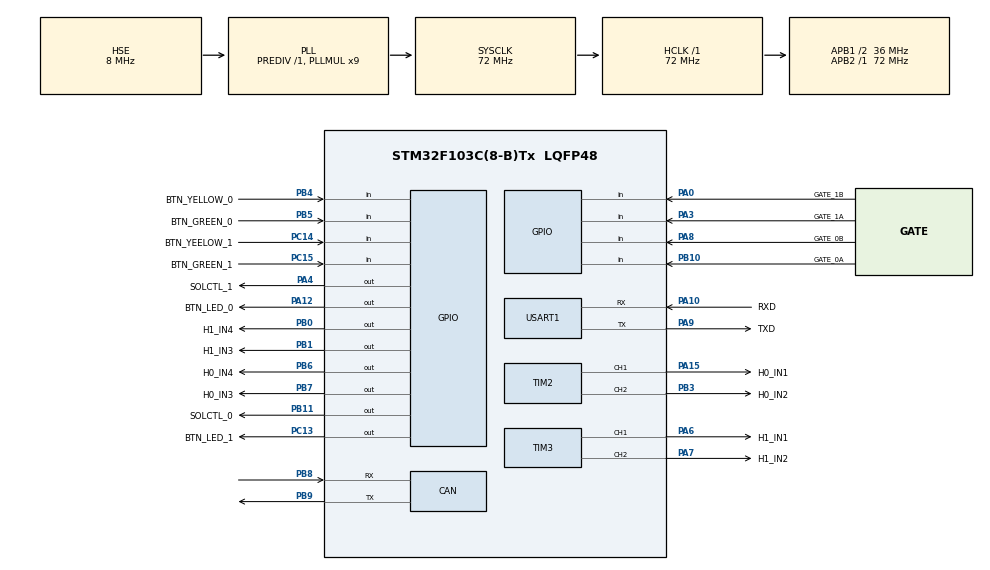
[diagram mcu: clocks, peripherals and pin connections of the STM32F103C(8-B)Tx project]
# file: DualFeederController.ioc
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CAN.CalculateTimeBit=1333
CAN.CalculateTimeQuantum=444.44444444444446
FREERTOS.Tasks01=defaultTask,0,128,StartDefaultTask,Default,NULL
Mcu.Family=STM32F1
Mcu.Name=STM32F103C(8-B)Tx
Mcu.Package=LQFP48
NVIC.PriorityGroup=NVIC_PRIORITYGROUP_4
NVIC.TIM4_IRQn=true\:0\:0\:false\:false\:true\:false\:false\:true
NVIC.TimeBase=TIM4_IRQn
NVIC.TimeBaseIP=TIM4
PA0-WKUP.GPIO_Label=GATE_1B
PA0-WKUP.Signal=GPIO_Input
PA10.GPIO_Label=RXD
PA10.Mode=Asynchronous
PA10.Signal=USART1_RX
PA12.GPIO_Label=BTN_LED_0
PA12.Signal=GPIO_Output
PA13.Mode=Serial_Wire
PA13.Signal=SYS_JTMS-SWDIO
PA14.Mode=Serial_Wire
PA14.Signal=SYS_JTCK-SWCLK
PA15.GPIO_Label=H0_IN1
PA15.Signal=S_TIM2_CH1_ETR
PA3.GPIO_Label=GATE_1A
PA3.Signal=GPIO_Input
PA4.GPIO_Label=SOLCTL_1
PA4.Signal=GPIO_Output
PA6.GPIO_Label=H1_IN1
PA6.Signal=S_TIM3_CH1
PA7.GPIO_Label=H1_IN2
PA7.Signal=S_TIM3_CH2
PA8.GPIO_Label=GATE_0B
PA8.Signal=GPIO_Input
PA9.GPIO_Label=TXD
PA9.Mode=Asynchronous
PA9.Signal=USART1_TX
PB0.GPIO_Label=H1_IN4
PB0.Signal=GPIO_Output
PB1.GPIO_Label=H1_IN3
PB1.Signal=GPIO_Output
PB10.GPIO_Label=GATE_0A
PB10.Signal=GPIO_Input
PB11.GPIO_Label=SOLCTL_0
PB11.Signal=GPIO_Output
PB3.GPIO_Label=H0_IN2
PB3.Signal=S_TIM2_CH2
PB4.GPIO_Label=BTN_YELLOW_0
PB4.Signal=GPIO_Input
PB5.GPIO_Label=BTN_GREEN_0
PB5.Signal=GPIO_Input
PB6.GPIO_Label=H0_IN4
PB6.Signal=GPIO_Output
PB7.GPIO_Label=H0_IN3
PB7.Signal=GPIO_Output
PB8.Mode=Master
PB8.Signal=CAN_RX
PB9.Mode=Master
PB9.Signal=CAN_TX
PC13-TAMPER-RTC.GPIO_Label=BTN_LED_1
PC13-TAMPER-RTC.Signal=GPIO_Output
PC14-OSC32_IN.GPIO_Label=BTN_YEELOW_1
PC14-OSC32_IN.Signal=GPIO_Input
PC15-OSC32_OUT.GPIO_Label=BTN_GREEN_1
PC15-OSC32_OUT.Signal=GPIO_Input
PD0-OSC_IN.Mode=HSE-External-Oscillator
PD0-OSC_IN.Signal=RCC_OSC_IN
PD1-OSC_OUT.Mode=HSE-External-Oscillator
PD1-OSC_OUT.Signal=RCC_OSC_OUT
ProjectManager.HeapSize=0x200
ProjectManager.StackSize=0x400
ProjectManager.TargetToolchain=MDK-ARM V5
RCC.AHBFreq_Value=72000000
RCC.APB1CLKDivider=RCC_HCLK_DIV2
RCC.APB1Freq_Value=36000000
RCC.APB1TimFreq_Value=72000000
RCC.APB2Freq_Value=72000000
RCC.APB2TimFreq_Value=72000000
RCC.HCLKFreq_Value=72000000
RCC.PLLMUL=RCC_PLL_MUL9
RCC.PLLSourceVirtual=RCC_PLLSOURCE_HSE
RCC.SYSCLKFreq_VALUE=72000000
RCC.SYSCLKSource=RCC_SYSCLKSOURCE_PLLCLK
RCC.USBFreq_Value=72000000
SH.S_TIM2_CH1_ETR.0=TIM2_CH1,PWM Generation1 CH1
SH.S_TIM2_CH2.0=TIM2_CH2,PWM Generation2 CH2
SH.S_TIM3_CH1.0=TIM3_CH1,PWM Generation1 CH1
SH.S_TIM3_CH2.0=TIM3_CH2,PWM Generation2 CH2
TIM2.Channel-PWM\ Generation1\ CH1=TIM_CHANNEL_1
TIM2.Channel-PWM\ Generation2\ CH2=TIM_CHANNEL_2
TIM3.Channel-PWM\ Generation1\ CH1=TIM_CHANNEL_1
TIM3.Channel-PWM\ Generation2\ CH2=TIM_CHANNEL_2
USART1.VirtualMode=VM_ASYNC
VP_FREERTOS_VS_CMSIS_V1.Mode=CMSIS_V1
VP_SYS_VS_tim4.Mode=TIM4
board=custom

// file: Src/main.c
/* USER CODE BEGIN Header */
/**
  ******************************************************************************
  * @file           : main.c
  * @brief          : Main program body
  ******************************************************************************
  * @attention
  *
  * <h2><center>&copy; Copyright (c) 2019 STMicroelectronics.
  * All rights reserved.</center></h2>
  *
  * This software component is licensed by ST under Ultimate Liberty license
  * SLA0044, the "License"; You may not use this file except in compliance with
  * the License. You may obtain a copy of the License at:
  *                             www.st.com/SLA0044
  *
  ******************************************************************************
  */
/* USER CODE END Header */

#include "main.h"
#include "cmsis_os.h"

CAN_HandleTypeDef hcan;

TIM_HandleTypeDef htim2;
TIM_HandleTypeDef htim3;

UART_HandleTypeDef huart1;

osThreadId defaultTaskHandle;

void SystemClock_Config(void);
static void MX_GPIO_Init(void);
static void MX_CAN_Init(void);
static void MX_USART1_UART_Init(void);
static void MX_TIM2_Init(void);
static void MX_TIM3_Init(void);
void StartDefaultTask(void const * argument);

/* USER CODE BEGIN 0 */
#if 1
#pragma import(__use_no_semihosting)
//标准库需要的支持函数
struct __FILE
{
	int handle;
};

FILE __stdout;
//定义_sys_exit()以避免使用半主机模式
void _sys_exit(int x)
{
	x = x;
}
//重定义fputc函数
int fputc(int ch, FILE *f)
{
	while((USART1->SR&0X40)==0);//循环发送,直到发送完毕
	USART1->DR = (uint8_t) ch;
	return ch;
}
#endif
/* USER CODE END 0 */

int main(void)
{

  /* MCU Configuration--------------------------------------------------------*/

  /* Reset of all peripherals, Initializes the Flash interface and the Systick. */
  HAL_Init();

  /* Configure the system clock */
  SystemClock_Config();

  /* Initialize all configured peripherals */
  MX_GPIO_Init();
  MX_CAN_Init();
  MX_USART1_UART_Init();
  MX_TIM2_Init();
  MX_TIM3_Init();
  /* USER CODE BEGIN 2 */

  printf("System ON\r\n");

  while(1)
  {
	  // 按键部分测试
//	  printf("BTN_GREEN_1 = %d  ", HAL_GPIO_ReadPin(BTN_GREEN_1_GPIO_Port, BTN_GREEN_1_Pin));  // 待机状态为 0
//	  printf("BTN_YELLOW_1 = %d\r\n", HAL_GPIO_ReadPin(BTN_YELLOW_1_GPIO_Port, BTN_YELLOW_1_Pin));  // 待机状态为 0
//	  HAL_GPIO_TogglePin(BTN_LED_1_GPIO_Port, BTN_LED_1_Pin);
//	  HAL_GPIO_WritePin(BTN_LED_1_GPIO_Port, BTN_LED_1_Pin, GPIO_PIN_SET);        // 待机状态为 0

	  // 后部光电开关测试
//	  printf("LIGH_GATE1B = %d\r\n", HAL_GPIO_ReadPin(GATE_1B_GPIO_Port, GATE_1B_Pin));   // 待机状态为 0

	  // 后部电机测试
//	  HAL_GPIO_WritePin(H1_IN3_GPIO_Port, H1_IN3_Pin , GPIO_PIN_RESET);
//	  HAL_GPIO_WritePin(H1_IN4_GPIO_Port, H1_IN4_Pin , GPIO_PIN_SET);

	  // 光电开关配合和电机测试
//	  if(HAL_GPIO_ReadPin(GATE_1B_GPIO_Port, GATE_1B_Pin) == GPIO_PIN_RESET)
//	  {
//		  HAL_GPIO_WritePin(H1_IN3_GPIO_Port, H1_IN3_Pin , GPIO_PIN_RESET);
//		  HAL_GPIO_WritePin(H1_IN4_GPIO_Port, H1_IN4_Pin , GPIO_PIN_SET);
//	  }
//	  else
//	  {
//		  // 刹车测试
//		  HAL_GPIO_WritePin(H1_IN3_GPIO_Port, H1_IN3_Pin , GPIO_PIN_SET);
//		  HAL_GPIO_WritePin(H1_IN4_GPIO_Port, H1_IN4_Pin , GPIO_PIN_SET);
//	  }

	  // 电磁挡板测试
//	  if(HAL_GPIO_ReadPin(BTN_YELLOW_1_GPIO_Port, BTN_YELLOW_1_Pin) == GPIO_PIN_SET)
//	  {
//		  HAL_GPIO_WritePin(SOLCTL_1_GPIO_Port, SOLCTL_1_Pin , GPIO_PIN_SET);
//	  }
//	  else
//	  {
//		  HAL_GPIO_WritePin(SOLCTL_1_GPIO_Port, SOLCTL_1_Pin , GPIO_PIN_RESET);
//	  }

//	  // 前部电机测试, 正转
//	  TIM3->CCR1 = 0;
//	  TIM3->CCR2 = 1000;
//	  HAL_TIM_PWM_Start(&htim3, TIM_CHANNEL_1);
//	  HAL_TIM_PWM_Start(&htim3, TIM_CHANNEL_2);

//	  // 前部光电开关测试
//	  printf("LIGH_GATE1A = %d\r\n", HAL_GPIO_ReadPin(GATE_1A_GPIO_Port, GATE_1A_Pin));

	  HAL_Delay(20);
  }

  /* USER CODE END 2 */

  /* Create the thread(s) */
  /* definition and creation of defaultTask */
  osThreadDef(defaultTask, StartDefaultTask, osPriorityNormal, 0, 128);
  defaultTaskHandle = osThreadCreate(osThread(defaultTask), NULL);

  /* Start scheduler */
  osKernelStart();

  /* We should never get here as control is now taken by the scheduler */

  /* Infinite loop */
  while (1)
  {

  }
}

void SystemClock_Config(void)
{
  RCC_OscInitTypeDef RCC_OscInitStruct = {0};
  RCC_ClkInitTypeDef RCC_ClkInitStruct = {0};

  /** Initializes the CPU, AHB and APB busses clocks
  */
  RCC_OscInitStruct.OscillatorType = RCC_OSCILLATORTYPE_HSE;
  RCC_OscInitStruct.HSEState = RCC_HSE_ON;
  RCC_OscInitStruct.HSEPredivValue = RCC_HSE_PREDIV_DIV1;
  RCC_OscInitStruct.HSIState = RCC_HSI_ON;
  RCC_OscInitStruct.PLL.PLLState = RCC_PLL_ON;
  RCC_OscInitStruct.PLL.PLLSource = RCC_PLLSOURCE_HSE;
  RCC_OscInitStruct.PLL.PLLMUL = RCC_PLL_MUL9;
  if (HAL_RCC_OscConfig(&RCC_OscInitStruct) != HAL_OK)
  {
    Error_Handler();
  }
  /** Initializes the CPU, AHB and APB busses clocks
  */
  RCC_ClkInitStruct.ClockType = RCC_CLOCKTYPE_HCLK|RCC_CLOCKTYPE_SYSCLK
                              |RCC_CLOCKTYPE_PCLK1|RCC_CLOCKTYPE_PCLK2;
  RCC_ClkInitStruct.SYSCLKSource = RCC_SYSCLKSOURCE_PLLCLK;
  RCC_ClkInitStruct.AHBCLKDivider = RCC_SYSCLK_DIV1;
  RCC_ClkInitStruct.APB1CLKDivider = RCC_HCLK_DIV2;
  RCC_ClkInitStruct.APB2CLKDivider = RCC_HCLK_DIV1;

  if (HAL_RCC_ClockConfig(&RCC_ClkInitStruct, FLASH_LATENCY_2) != HAL_OK)
  {
    Error_Handler();
  }
}

static void MX_CAN_Init(void)
{

  hcan.Instance = CAN1;
  hcan.Init.Prescaler = 16;
  hcan.Init.Mode = CAN_MODE_NORMAL;
  hcan.Init.SyncJumpWidth = CAN_SJW_1TQ;
  hcan.Init.TimeSeg1 = CAN_BS1_1TQ;
  hcan.Init.TimeSeg2 = CAN_BS2_1TQ;
  hcan.Init.TimeTriggeredMode = DISABLE;
  hcan.Init.AutoBusOff = DISABLE;
  hcan.Init.AutoWakeUp = DISABLE;
  hcan.Init.AutoRetransmission = DISABLE;
  hcan.Init.ReceiveFifoLocked = DISABLE;
  hcan.Init.TransmitFifoPriority = DISABLE;
  if (HAL_CAN_Init(&hcan) != HAL_OK)
  {
    Error_Handler();
  }

}

static void MX_TIM2_Init(void)
{

  TIM_MasterConfigTypeDef sMasterConfig = {0};
  TIM_OC_InitTypeDef sConfigOC = {0};

  htim2.Instance = TIM2;
  htim2.Init.Prescaler = 6;
  htim2.Init.CounterMode = TIM_COUNTERMODE_UP;
  htim2.Init.Period = 1000;
  htim2.Init.ClockDivision = TIM_CLOCKDIVISION_DIV1;
  htim2.Init.AutoReloadPreload = TIM_AUTORELOAD_PRELOAD_DISABLE;
  if (HAL_TIM_PWM_Init(&htim2) != HAL_OK)
  {
    Error_Handler();
  }
  sMasterConfig.MasterOutputTrigger = TIM_TRGO_RESET;
  sMasterConfig.MasterSlaveMode = TIM_MASTERSLAVEMODE_DISABLE;
  if (HAL_TIMEx_MasterConfigSynchronization(&htim2, &sMasterConfig) != HAL_OK)
  {
    Error_Handler();
  }
  sConfigOC.OCMode = TIM_OCMODE_PWM1;
  sConfigOC.Pulse = 0;
  sConfigOC.OCPolarity = TIM_OCPOLARITY_HIGH;
  sConfigOC.OCFastMode = TIM_OCFAST_DISABLE;
  if (HAL_TIM_PWM_ConfigChannel(&htim2, &sConfigOC, TIM_CHANNEL_1) != HAL_OK)
  {
    Error_Handler();
  }
  if (HAL_TIM_PWM_ConfigChannel(&htim2, &sConfigOC, TIM_CHANNEL_2) != HAL_OK)
  {
    Error_Handler();
  }
  HAL_TIM_MspPostInit(&htim2);

}

static void MX_TIM3_Init(void)
{

  TIM_MasterConfigTypeDef sMasterConfig = {0};
  TIM_OC_InitTypeDef sConfigOC = {0};

  htim3.Instance = TIM3;
  htim3.Init.Prescaler = 6;
  htim3.Init.CounterMode = TIM_COUNTERMODE_UP;
  htim3.Init.Period = 1000;
  htim3.Init.ClockDivision = TIM_CLOCKDIVISION_DIV1;
  htim3.Init.AutoReloadPreload = TIM_AUTORELOAD_PRELOAD_DISABLE;
  if (HAL_TIM_PWM_Init(&htim3) != HAL_OK)
  {
    Error_Handler();
  }
  sMasterConfig.MasterOutputTrigger = TIM_TRGO_RESET;
  sMasterConfig.MasterSlaveMode = TIM_MASTERSLAVEMODE_DISABLE;
  if (HAL_TIMEx_MasterConfigSynchronization(&htim3, &sMasterConfig) != HAL_OK)
  {
    Error_Handler();
  }
  sConfigOC.OCMode = TIM_OCMODE_PWM1;
  sConfigOC.Pulse = 0;
  sConfigOC.OCPolarity = TIM_OCPOLARITY_HIGH;
  sConfigOC.OCFastMode = TIM_OCFAST_DISABLE;
  if (HAL_TIM_PWM_ConfigChannel(&htim3, &sConfigOC, TIM_CHANNEL_1) != HAL_OK)
  {
    Error_Handler();
  }
  if (HAL_TIM_PWM_ConfigChannel(&htim3, &sConfigOC, TIM_CHANNEL_2) != HAL_OK)
  {
    Error_Handler();
  }
  HAL_TIM_MspPostInit(&htim3);

}

static void MX_USART1_UART_Init(void)
{

  huart1.Instance = USART1;
  huart1.Init.BaudRate = 115200;
  huart1.Init.WordLength = UART_WORDLENGTH_8B;
  huart1.Init.StopBits = UART_STOPBITS_1;
  huart1.Init.Parity = UART_PARITY_NONE;
  huart1.Init.Mode = UART_MODE_TX_RX;
  huart1.Init.HwFlowCtl = UART_HWCONTROL_NONE;
  huart1.Init.OverSampling = UART_OVERSAMPLING_16;
  if (HAL_UART_Init(&huart1) != HAL_OK)
  {
    Error_Handler();
  }

}

static void MX_GPIO_Init(void)
{
  GPIO_InitTypeDef GPIO_InitStruct = {0};

  /* GPIO Ports Clock Enable */
  __HAL_RCC_GPIOC_CLK_ENABLE();
  __HAL_RCC_GPIOD_CLK_ENABLE();
  __HAL_RCC_GPIOA_CLK_ENABLE();
  __HAL_RCC_GPIOB_CLK_ENABLE();

  /*Configure GPIO pin Output Level */
  HAL_GPIO_WritePin(BTN_LED_1_GPIO_Port, BTN_LED_1_Pin, GPIO_PIN_RESET);

  /*Configure GPIO pin Output Level */
  HAL_GPIO_WritePin(GPIOA, SOLCTL_1_Pin|BTN_LED_0_Pin, GPIO_PIN_RESET);

  /*Configure GPIO pin Output Level */
  HAL_GPIO_WritePin(GPIOB, H1_IN4_Pin|H1_IN3_Pin|SOLCTL_0_Pin|H0_IN4_Pin
                          |H0_IN3_Pin, GPIO_PIN_RESET);

  /*Configure GPIO pin : BTN_LED_1_Pin */
  GPIO_InitStruct.Pin = BTN_LED_1_Pin;
  GPIO_InitStruct.Mode = GPIO_MODE_OUTPUT_PP;
  GPIO_InitStruct.Pull = GPIO_NOPULL;
  GPIO_InitStruct.Speed = GPIO_SPEED_FREQ_LOW;
  HAL_GPIO_Init(BTN_LED_1_GPIO_Port, &GPIO_InitStruct);

  /*Configure GPIO pins : BTN_YEELOW_1_Pin BTN_GREEN_1_Pin */
  GPIO_InitStruct.Pin = BTN_YELLOW_1_Pin|BTN_GREEN_1_Pin;
  GPIO_InitStruct.Mode = GPIO_MODE_INPUT;
  GPIO_InitStruct.Pull = GPIO_NOPULL;
  HAL_GPIO_Init(GPIOC, &GPIO_InitStruct);

  /*Configure GPIO pins : GATE_1B_Pin GATE_1A_Pin GATE_0B_Pin */
  GPIO_InitStruct.Pin = GATE_1B_Pin|GATE_1A_Pin|GATE_0B_Pin;
  GPIO_InitStruct.Mode = GPIO_MODE_INPUT;
  GPIO_InitStruct.Pull = GPIO_NOPULL;
  HAL_GPIO_Init(GPIOA, &GPIO_InitStruct);

  /*Configure GPIO pins : SOLCTL_1_Pin BTN_LED_0_Pin */
  GPIO_InitStruct.Pin = SOLCTL_1_Pin|BTN_LED_0_Pin;
  GPIO_InitStruct.Mode = GPIO_MODE_OUTPUT_PP;
  GPIO_InitStruct.Pull = GPIO_NOPULL;
  GPIO_InitStruct.Speed = GPIO_SPEED_FREQ_LOW;
  HAL_GPIO_Init(GPIOA, &GPIO_InitStruct);

  /*Configure GPIO pins : H1_IN4_Pin H1_IN3_Pin SOLCTL_0_Pin H0_IN4_Pin
                           H0_IN3_Pin */
  GPIO_InitStruct.Pin = H1_IN4_Pin|H1_IN3_Pin|SOLCTL_0_Pin|H0_IN4_Pin
                          |H0_IN3_Pin;
  GPIO_InitStruct.Mode = GPIO_MODE_OUTPUT_PP;
  GPIO_InitStruct.Pull = GPIO_NOPULL;
  GPIO_InitStruct.Speed = GPIO_SPEED_FREQ_LOW;
  HAL_GPIO_Init(GPIOB, &GPIO_InitStruct);

  /*Configure GPIO pins : GATE_0A_Pin BTN_YELLOW_0_Pin BTN_GREEN_0_Pin */
  GPIO_InitStruct.Pin = GATE_0A_Pin|BTN_YELLOW_0_Pin|BTN_GREEN_0_Pin;
  GPIO_InitStruct.Mode = GPIO_MODE_INPUT;
  GPIO_InitStruct.Pull = GPIO_NOPULL;
  HAL_GPIO_Init(GPIOB, &GPIO_InitStruct);

}

void StartDefaultTask(void const * argument)
{

  for(;;)
  {
    osDelay(1);
  }
}

void HAL_TIM_PeriodElapsedCallback(TIM_HandleTypeDef *htim)
{
  if (htim->Instance == TIM4) {
    HAL_IncTick();
  }
}

void Error_Handler(void)
{
}

/************************ (C) COPYRIGHT STMicroelectronics *****END OF FILE****/
